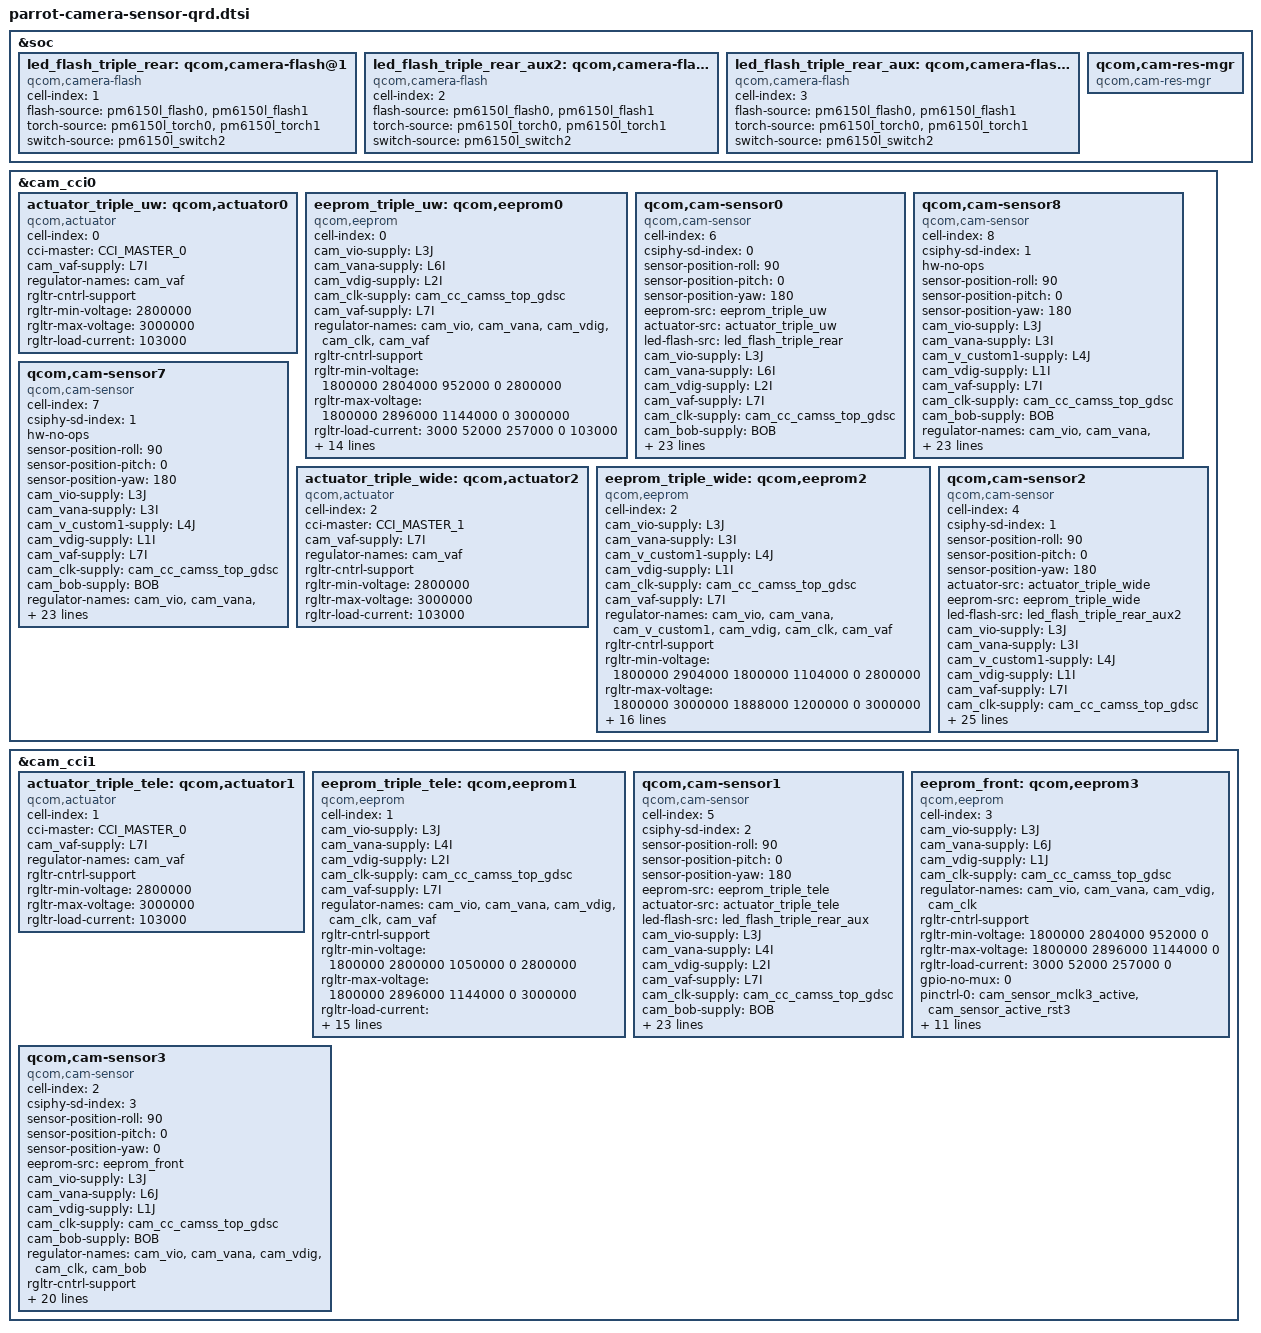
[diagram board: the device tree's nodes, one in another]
#include <dt-bindings/clock/qcom,camcc-parrot.h>
#include <dt-bindings/msm-camera.h>

&soc {
	led_flash_triple_rear: qcom,camera-flash@1 {
		cell-index = <1>;
		compatible = "qcom,camera-flash";
		flash-source = <&pm6150l_flash0 &pm6150l_flash1>;
		torch-source = <&pm6150l_torch0 &pm6150l_torch1>;
		switch-source = <&pm6150l_switch2>;
		status = "ok";
	};

	led_flash_triple_rear_aux2: qcom,camera-flash@2 {
		cell-index = <2>;
		compatible = "qcom,camera-flash";
		flash-source = <&pm6150l_flash0 &pm6150l_flash1>;
		torch-source = <&pm6150l_torch0 &pm6150l_torch1>;
		switch-source = <&pm6150l_switch2>;
		status = "ok";
	};

	led_flash_triple_rear_aux: qcom,camera-flash@3 {
		cell-index = <3>;
		compatible = "qcom,camera-flash";
		flash-source = <&pm6150l_flash0 &pm6150l_flash1>;
		torch-source = <&pm6150l_torch0 &pm6150l_torch1>;
		switch-source = <&pm6150l_switch2>;
		status = "ok";
	};

	qcom,cam-res-mgr {
		compatible = "qcom,cam-res-mgr";
		status = "ok";
	};
};

&cam_cci0 {
	actuator_triple_uw: qcom,actuator0 {
		cell-index = <0>;
		compatible = "qcom,actuator";
		cci-master = <CCI_MASTER_0>;
		cam_vaf-supply = <&L7I>;
		regulator-names = "cam_vaf";
		rgltr-cntrl-support;
		rgltr-min-voltage = <2800000>;
		rgltr-max-voltage = <3000000>;
		rgltr-load-current = <103000>;
	};

	eeprom_triple_uw: qcom,eeprom0 {
		cell-index = <0>;
		compatible = "qcom,eeprom";
		cam_vio-supply = <&L3J>;
		cam_vana-supply = <&L6I>;
		cam_vdig-supply = <&L2I>;
		cam_clk-supply = <&cam_cc_camss_top_gdsc>;
		cam_vaf-supply = <&L7I>;
		regulator-names = "cam_vio", "cam_vana", "cam_vdig",
			"cam_clk", "cam_vaf";
		rgltr-cntrl-support;
		rgltr-min-voltage = <1800000 2804000 952000 0 2800000>;
		rgltr-max-voltage = <1800000 2896000 1144000 0 3000000>;
		rgltr-load-current = <3000 52000 257000 0 103000>;
		gpio-no-mux = <0>;
		pinctrl-names = "cam_default", "cam_suspend";
		pinctrl-0 = <&cam_sensor_mclk0_active
				 &cam_sensor_active_rst0>;
		pinctrl-1 = <&cam_sensor_mclk0_suspend
				 &cam_sensor_suspend_rst0>;
		gpios = <&tlmm 39 0>,
			<&tlmm 44 0>;
		gpio-reset = <1>;
		gpio-req-tbl-num = <0 1>;
		gpio-req-tbl-flags = <1 0>;
		gpio-req-tbl-label = "CAMIF_MCLK0",
					"CAM_RESET0";
		cci-master = <CCI_MASTER_0>;
		clocks = <&camcc CAM_CC_MCLK0_CLK>;
		clock-names = "cam_clk";
		clock-cntl-level = "nominal";
		clock-rates = <24000000>;
		status = "ok";
	};

	qcom,cam-sensor0 {
		cell-index = <6>;
		compatible = "qcom,cam-sensor";
		csiphy-sd-index = <0>;
		sensor-position-roll = <90>;
		sensor-position-pitch = <0>;
		sensor-position-yaw = <180>;
		eeprom-src = <&eeprom_triple_uw>;
		actuator-src = <&actuator_triple_uw>;
		led-flash-src = <&led_flash_triple_rear>;
		cam_vio-supply = <&L3J>;
		cam_vana-supply = <&L6I>;
		cam_vdig-supply = <&L2I>;
		cam_vaf-supply = <&L7I>;
		cam_clk-supply = <&cam_cc_camss_top_gdsc>;
		cam_bob-supply = <&BOB>;
		regulator-names = "cam_vio", "cam_vana", "cam_vdig",
			"cam_vaf", "cam_clk", "cam_bob";
		rgltr-cntrl-support;
		rgltr-min-voltage = <1800000 2804000 1070000 2800000 0 3008000>;
		rgltr-max-voltage = <1800000 2896000 1338460 3000000 0 3960000>;
		rgltr-load-current = <3000 52000 257000 103000 0 7840000>;
		gpio-no-mux = <0>;
		pinctrl-names = "cam_default", "cam_suspend";
		pinctrl-0 = <&cam_sensor_mclk0_active
				 &cam_sensor_active_rst0>;
		pinctrl-1 = <&cam_sensor_mclk0_suspend
				 &cam_sensor_suspend_rst0>;
		gpios = <&tlmm 39 0>,
			<&tlmm 44 0>;
		gpio-reset = <1>;
		gpio-req-tbl-num = <0 1>;
		gpio-req-tbl-flags = <1 0>;
		gpio-req-tbl-label = "CAMIF_MCLK0",
					"CAM_RESET0";
		cci-master = <CCI_MASTER_0>;
		clocks = <&camcc CAM_CC_MCLK0_CLK>;
		clock-names = "cam_clk";
		clock-cntl-level = "nominal";
		clock-rates = <24000000>;
		status = "ok";
	};

	qcom,cam-sensor8 {
		cell-index = <8>;
		compatible = "qcom,cam-sensor";
		csiphy-sd-index = <1>;
		hw-no-ops;
		sensor-position-roll = <90>;
		sensor-position-pitch = <0>;
		sensor-position-yaw = <180>;
		cam_vio-supply = <&L3J>;
		cam_vana-supply = <&L3I>;
		cam_v_custom1-supply = <&L4J>;
		cam_vdig-supply = <&L1I>;
		cam_vaf-supply = <&L7I>;
		cam_clk-supply = <&cam_cc_camss_top_gdsc>;
		cam_bob-supply = <&BOB>;
		regulator-names = "cam_vio", "cam_vana", "cam_v_custom1",
			"cam_vdig", "cam_vaf", "cam_clk", "cam_bob";
		rgltr-cntrl-support;
		rgltr-min-voltage = <1808000 2904000 1800000 1104000 2704000 0 3008000>;
		rgltr-max-voltage = <1808000 3000000 1888000 1200000 3000000 0 3960000>;
		rgltr-load-current = <4000 96000 88000 872000 103000 0 8570000>;
		gpio-no-mux = <0>;
		pinctrl-names = "cam_default", "cam_suspend";
		pinctrl-0 = <&cam_sensor_mclk2_active
				&cam_sensor_active_rst2>;
		pinctrl-1 = <&cam_sensor_mclk2_suspend
				&cam_sensor_suspend_rst2>;
		gpios = <&tlmm 41 0>,
			<&tlmm 46 0>;
		gpio-reset = <1>;
		gpio-req-tbl-num = <0 1>;
		gpio-req-tbl-flags = <1 0>;
		gpio-req-tbl-label = "CAMIF_MCLK2",
					"CAM_RESET2";
		cci-master = <CCI_MASTER_1>;
		clocks = <&camcc CAM_CC_MCLK2_CLK>;
		clock-names = "cam_clk";
		clock-cntl-level = "nominal";
		clock-rates = <24000000>;
		status = "ok";
	};

	qcom,cam-sensor7 {
		cell-index = <7>;
		compatible = "qcom,cam-sensor";
		csiphy-sd-index = <1>;
		hw-no-ops;
		sensor-position-roll = <90>;
		sensor-position-pitch = <0>;
		sensor-position-yaw = <180>;
		cam_vio-supply = <&L3J>;
		cam_vana-supply = <&L3I>;
		cam_v_custom1-supply = <&L4J>;
		cam_vdig-supply = <&L1I>;
		cam_vaf-supply = <&L7I>;
		cam_clk-supply = <&cam_cc_camss_top_gdsc>;
		cam_bob-supply = <&BOB>;
		regulator-names = "cam_vio", "cam_vana", "cam_v_custom1",
			"cam_vdig", "cam_vaf", "cam_clk", "cam_bob";
		rgltr-cntrl-support;
		rgltr-min-voltage = <1808000 2904000 1800000 1104000 2704000 0 3008000>;
		rgltr-max-voltage = <1808000 3000000 1888000 1200000 3000000 0 3960000>;
		rgltr-load-current = <4000 96000 88000 872000 103000 0 8570000>;
		gpio-no-mux = <0>;
		pinctrl-names = "cam_default", "cam_suspend";
		pinctrl-0 = <&cam_sensor_mclk2_active
				&cam_sensor_active_rst2>;
		pinctrl-1 = <&cam_sensor_mclk2_suspend
				&cam_sensor_suspend_rst2>;
		gpios = <&tlmm 41 0>,
			<&tlmm 46 0>;
		gpio-reset = <1>;
		gpio-req-tbl-num = <0 1>;
		gpio-req-tbl-flags = <1 0>;
		gpio-req-tbl-label = "CAMIF_MCLK2",
					"CAM_RESET2";
		cci-master = <CCI_MASTER_1>;
		clocks = <&camcc CAM_CC_MCLK2_CLK>;
		clock-names = "cam_clk";
		clock-cntl-level = "nominal";
		clock-rates = <24000000>;
		status = "ok";
	};

	actuator_triple_wide: qcom,actuator2 {
		cell-index = <2>;
		compatible = "qcom,actuator";
		cci-master = <CCI_MASTER_1>;
		cam_vaf-supply = <&L7I>;
		regulator-names = "cam_vaf";
		rgltr-cntrl-support;
		rgltr-min-voltage = <2800000>;
		rgltr-max-voltage = <3000000>;
		rgltr-load-current = <103000>;
	};

	eeprom_triple_wide: qcom,eeprom2 {
		cell-index = <2>;
		compatible = "qcom,eeprom";
		cam_vio-supply = <&L3J>;
		cam_vana-supply = <&L3I>;
		cam_v_custom1-supply = <&L4J>;
		cam_vdig-supply = <&L1I>;
		cam_clk-supply = <&cam_cc_camss_top_gdsc>;
		cam_vaf-supply = <&L7I>;
		regulator-names = "cam_vio", "cam_vana", "cam_v_custom1",
			"cam_vdig", "cam_clk", "cam_vaf";
		rgltr-cntrl-support;
		rgltr-min-voltage = <1800000 2904000 1800000 1104000 0 2800000>;
		rgltr-max-voltage = <1800000 3000000 1888000 1200000 0 3000000>;
		rgltr-load-current = <4000 96000 88000 872000 0 103000>;
		gpio-no-mux = <0>;
		pinctrl-names = "cam_default", "cam_suspend";
		pinctrl-0 = <&cam_sensor_mclk1_active
				&cam_sensor_active_rst1>;
		pinctrl-1 = <&cam_sensor_mclk1_suspend
				&cam_sensor_suspend_rst1>;
		gpios = <&tlmm 40 0>,
			<&tlmm 45 0>;
		gpio-reset = <1>;
		gpio-req-tbl-num = <0 1>;
		gpio-req-tbl-flags = <1 0>;
		gpio-req-tbl-label = "CAMIF_MCLK1",
					"CAM_RESET1";
		cci-master = <CCI_MASTER_1>;
		clocks = <&camcc CAM_CC_MCLK1_CLK>;
		clock-names = "cam_clk";
		clock-cntl-level = "nominal";
		clock-rates = <24000000>;
		status = "ok";
	};

	qcom,cam-sensor2 {
		cell-index = <4>;
		compatible = "qcom,cam-sensor";
		csiphy-sd-index = <1>;
		sensor-position-roll = <90>;
		sensor-position-pitch = <0>;
		sensor-position-yaw = <180>;
		actuator-src = <&actuator_triple_wide>;
		eeprom-src = <&eeprom_triple_wide>;
		led-flash-src = <&led_flash_triple_rear_aux2>;
		cam_vio-supply = <&L3J>;
		cam_vana-supply = <&L3I>;
		cam_v_custom1-supply = <&L4J>;
		cam_vdig-supply = <&L1I>;
		cam_vaf-supply = <&L7I>;
		cam_clk-supply = <&cam_cc_camss_top_gdsc>;
		cam_bob-supply = <&BOB>;
		regulator-names = "cam_vio", "cam_vana", "cam_v_custom1",
			"cam_vdig", "cam_vaf", "cam_clk", "cam_bob";
		rgltr-cntrl-support;
		rgltr-min-voltage = <1800000 2904000 1800000 1104000 2800000 0 3008000>;
		rgltr-max-voltage = <1800000 3000000 1888000 1200000 3000000 0 3960000>;
		rgltr-load-current = <4000 96000 88000 872000 103000 0 7840000>;
		gpio-no-mux = <0>;
		pinctrl-names = "cam_default", "cam_suspend";
		pinctrl-0 = <&cam_sensor_mclk1_active
				&cam_sensor_active_rst1>;
		pinctrl-1 = <&cam_sensor_mclk1_suspend
				&cam_sensor_suspend_rst1>;
		gpios = <&tlmm 40 0>,
			<&tlmm 45 0>;
		gpio-reset = <1>;
		gpio-req-tbl-num = <0 1>;
		gpio-req-tbl-flags = <1 0>;
		gpio-req-tbl-label = "CAMIF_MCLK1",
					"CAM_RESET1";
		cci-master = <CCI_MASTER_1>;
		clocks = <&camcc CAM_CC_MCLK1_CLK>;
		clock-names = "cam_clk";
		clock-cntl-level = "nominal";
		clock-rates = <24000000>;
		status = "ok";
	};
};

&cam_cci1 {
	actuator_triple_tele: qcom,actuator1 {
		cell-index = <1>;
		compatible = "qcom,actuator";
		cci-master = <CCI_MASTER_0>;
		cam_vaf-supply = <&L7I>;
		regulator-names = "cam_vaf";
		rgltr-cntrl-support;
		rgltr-min-voltage = <2800000>;
		rgltr-max-voltage = <3000000>;
		rgltr-load-current = <103000>;
	};

	eeprom_triple_tele: qcom,eeprom1 {
		cell-index = <1>;
		compatible = "qcom,eeprom";
		cam_vio-supply = <&L3J>;
		cam_vana-supply = <&L4I>;
		cam_vdig-supply = <&L2I>;
		cam_clk-supply = <&cam_cc_camss_top_gdsc>;
		cam_vaf-supply = <&L7I>;
		regulator-names = "cam_vio", "cam_vana", "cam_vdig",
			"cam_clk", "cam_vaf";
		rgltr-cntrl-support;
		rgltr-min-voltage = <1800000 2800000 1050000 0 2800000>;
		rgltr-max-voltage = <1800000 2896000 1144000 0 3000000>;
		rgltr-load-current = <10000 52000 140000 0 103000>;
		gpio-no-mux = <0>;
		pinctrl-names = "cam_default", "cam_suspend";
		pinctrl-0 = <&cam_sensor_mclk2_active
				 &cam_sensor_active_rst2>;
		pinctrl-1 = <&cam_sensor_mclk2_suspend
				 &cam_sensor_suspend_rst2>;
		gpios = <&tlmm 41 0>,
			<&tlmm 46 0>;
		gpio-reset = <1>;
		gpio-req-tbl-num = <0 1>;
		gpio-req-tbl-flags = <1 0>;
		gpio-req-tbl-label = "CAMIF_MCLK2",
					"CAM_RESET2";
		cci-master = <CCI_MASTER_0>;
		clocks = <&camcc CAM_CC_MCLK2_CLK>;
		clock-names = "cam_clk";
		clock-cntl-level = "nominal";
		clock-rates = <24000000>;
		status = "ok";
	};

	qcom,cam-sensor1 {
		cell-index = <5>;
		compatible = "qcom,cam-sensor";
		csiphy-sd-index = <2>;
		sensor-position-roll = <90>;
		sensor-position-pitch = <0>;
		sensor-position-yaw = <180>;
		eeprom-src = <&eeprom_triple_tele>;
		actuator-src = <&actuator_triple_tele>;
		led-flash-src = <&led_flash_triple_rear_aux>;
		cam_vio-supply = <&L3J>;
		cam_vana-supply = <&L4I>;
		cam_vdig-supply = <&L2I>;
		cam_vaf-supply = <&L7I>;
		cam_clk-supply = <&cam_cc_camss_top_gdsc>;
		cam_bob-supply = <&BOB>;
		regulator-names = "cam_vio", "cam_vana", "cam_vdig",
			"cam_vaf", "cam_clk", "cam_bob";
		rgltr-cntrl-support;
		rgltr-min-voltage = <1800000 2800000 1050000 2800000 0 3008000>;
		rgltr-max-voltage = <1800000 2896000 1144000 3000000 0 3960000>;
		rgltr-load-current = <10000 52000 140000 103000 0 7840000>;
		gpio-no-mux = <0>;
		pinctrl-names = "cam_default", "cam_suspend";
		pinctrl-0 = <&cam_sensor_mclk2_active
				 &cam_sensor_active_rst2>;
		pinctrl-1 = <&cam_sensor_mclk2_suspend
				 &cam_sensor_suspend_rst2>;
		gpios = <&tlmm 41 0>,
			<&tlmm 46 0>;
		gpio-reset = <1>;
		gpio-req-tbl-num = <0 1>;
		gpio-req-tbl-flags = <1 0>;
		gpio-req-tbl-label = "CAMIF_MCLK2",
					"CAM_RESET2";
		cci-master = <CCI_MASTER_0>;
		clocks = <&camcc CAM_CC_MCLK2_CLK>;
		clock-names = "cam_clk";
		clock-cntl-level = "nominal";
		clock-rates = <24000000>;
		status = "ok";
	};

	eeprom_front: qcom,eeprom3 {
		cell-index = <3>;
		compatible = "qcom,eeprom";
		cam_vio-supply = <&L3J>;
		cam_vana-supply = <&L6J>;
		cam_vdig-supply = <&L1J>;
		cam_clk-supply = <&cam_cc_camss_top_gdsc>;
		regulator-names = "cam_vio", "cam_vana", "cam_vdig",
			"cam_clk";
		rgltr-cntrl-support;
		rgltr-min-voltage = <1800000 2804000 952000 0>;
		rgltr-max-voltage = <1800000 2896000 1144000 0>;
		rgltr-load-current = <3000 52000 257000 0>;
		gpio-no-mux = <0>;
		pinctrl-names = "cam_default", "cam_suspend";
		pinctrl-0 = <&cam_sensor_mclk3_active
				 &cam_sensor_active_rst3>;
		pinctrl-1 = <&cam_sensor_mclk3_suspend
				 &cam_sensor_suspend_rst3>;
		gpios = <&tlmm 42 0>,
			<&tlmm 47 0>;
		gpio-reset = <1>;
		gpio-req-tbl-num = <0 1>;
		gpio-req-tbl-flags = <1 0>;
		gpio-req-tbl-label = "CAMIF_MCLK3",
					"CAM_RESET3";
		cci-master = <CCI_MASTER_1>;
		clocks = <&camcc CAM_CC_MCLK3_CLK>;
		clock-names = "cam_clk";
		clock-cntl-level = "nominal";
		clock-rates = <24000000>;
		status = "ok";
	};

	qcom,cam-sensor3 {
		cell-index = <2>;
		compatible = "qcom,cam-sensor";
		csiphy-sd-index = <3>;
		sensor-position-roll = <90>;
		sensor-position-pitch = <0>;
		sensor-position-yaw = <0>;
		eeprom-src = <&eeprom_front>;
		cam_vio-supply = <&L3J>;
		cam_vana-supply = <&L6J>;
		cam_vdig-supply = <&L1J>;
		cam_clk-supply = <&cam_cc_camss_top_gdsc>;
		cam_bob-supply = <&BOB>;
		regulator-names = "cam_vio", "cam_vana", "cam_vdig",
			"cam_clk", "cam_bob";
		rgltr-cntrl-support;
		rgltr-min-voltage = <1800000 2804000 1070000 0 3008000>;
		rgltr-max-voltage = <1800000 2896000 1350320 0 3960000>;
		rgltr-load-current = <3000 52000 257000 0 7840000>;
		gpio-no-mux = <0>;
		pinctrl-names = "cam_default", "cam_suspend";
		pinctrl-0 = <&cam_sensor_mclk3_active
				 &cam_sensor_active_rst3>;
		pinctrl-1 = <&cam_sensor_mclk3_suspend
				 &cam_sensor_suspend_rst3>;
		gpios = <&tlmm 42 0>,
			<&tlmm 47 0>;
		gpio-reset = <1>;
		gpio-req-tbl-num = <0 1>;
		gpio-req-tbl-flags = <1 0>;
		gpio-req-tbl-label = "CAMIF_MCLK3",
					"CAM_RESET3";
		cci-master = <CCI_MASTER_1>;
		clocks = <&camcc CAM_CC_MCLK3_CLK>;
		clock-names = "cam_clk";
		clock-cntl-level = "nominal";
		clock-rates = <24000000>;
		status = "ok";
	};
};
